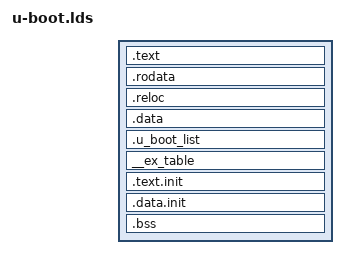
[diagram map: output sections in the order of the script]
/*
 * (C) Copyright 2000-2003
 * Wolfgang Denk, DENX Software Engineering, wd@denx.de.
 *
 * See file CREDITS for list of people who contributed to this
 * project.
 *
 * This program is free software; you can redistribute it and/or
 * modify it under the terms of the GNU General Public License as
 * published by the Free Software Foundation; either version 2 of
 * the License, or (at your option) any later version.
 *
 * This program is distributed in the hope that it will be useful,
 * but WITHOUT ANY WARRANTY; without even the implied warranty of
 * MERCHANTABILITY or FITNESS FOR A PARTICULAR PURPOSE.  See the
 * GNU General Public License for more details.
 *
 * You should have received a copy of the GNU General Public License
 * along with this program; if not, write to the Free Software
 * Foundation, Inc., 59 Temple Place, Suite 330, Boston,
 * MA 02111-1307 USA
 */

OUTPUT_ARCH(m68k)

SECTIONS
{
  .text      :
  {
    arch/m68k/cpu/mcf52x2/start.o	(.text*)

    . = DEFINED(env_offset) ? env_offset : .;
    common/env_embedded.o      (.text*)

    *(.text*)
  }
  _etext = .;
  PROVIDE (etext = .);
  .rodata    :
  {
    *(SORT_BY_ALIGNMENT(SORT_BY_NAME(.rodata*)))
  }

  /* Read-write section, merged into data segment: */
  . = (. + 0x00FF) & 0xFFFFFF00;
  _erotext = .;
  PROVIDE (erotext = .);

  .reloc   :
  {
    __got_start = .;
    KEEP(*(.got))
    __got_end = .;
    _GOT2_TABLE_ = .;
    KEEP(*(.got2))
    _FIXUP_TABLE_ = .;
    KEEP(*(.fixup))
  }
  __got2_entries = (_FIXUP_TABLE_ - _GOT2_TABLE_) >>2;
  __fixup_entries = (. - _FIXUP_TABLE_)>>2;

  .data    :
  {
    *(.data*)
    *(.sdata*)
  }
  _edata  =  .;
  PROVIDE (edata = .);

  . = .;

  . = ALIGN(4);
  .u_boot_list : {
	#include <u-boot.lst>
  }

  . = .;
  __start___ex_table = .;
  __ex_table : { *(__ex_table) }
  __stop___ex_table = .;

  . = ALIGN(256);
  __init_begin = .;
  .text.init : { *(.text.init) }
  .data.init : { *(.data.init) }
  . = ALIGN(256);
  __init_end = .;

  __bss_start = .;
  .bss (NOLOAD)      :
  {
   _sbss = .;
   *(.bss*)
   *(.sbss*)
   *(COMMON)
   . = ALIGN(4);
   _ebss = .;
  }
  __bss_end__ = . ;
  PROVIDE (end = .);
}
